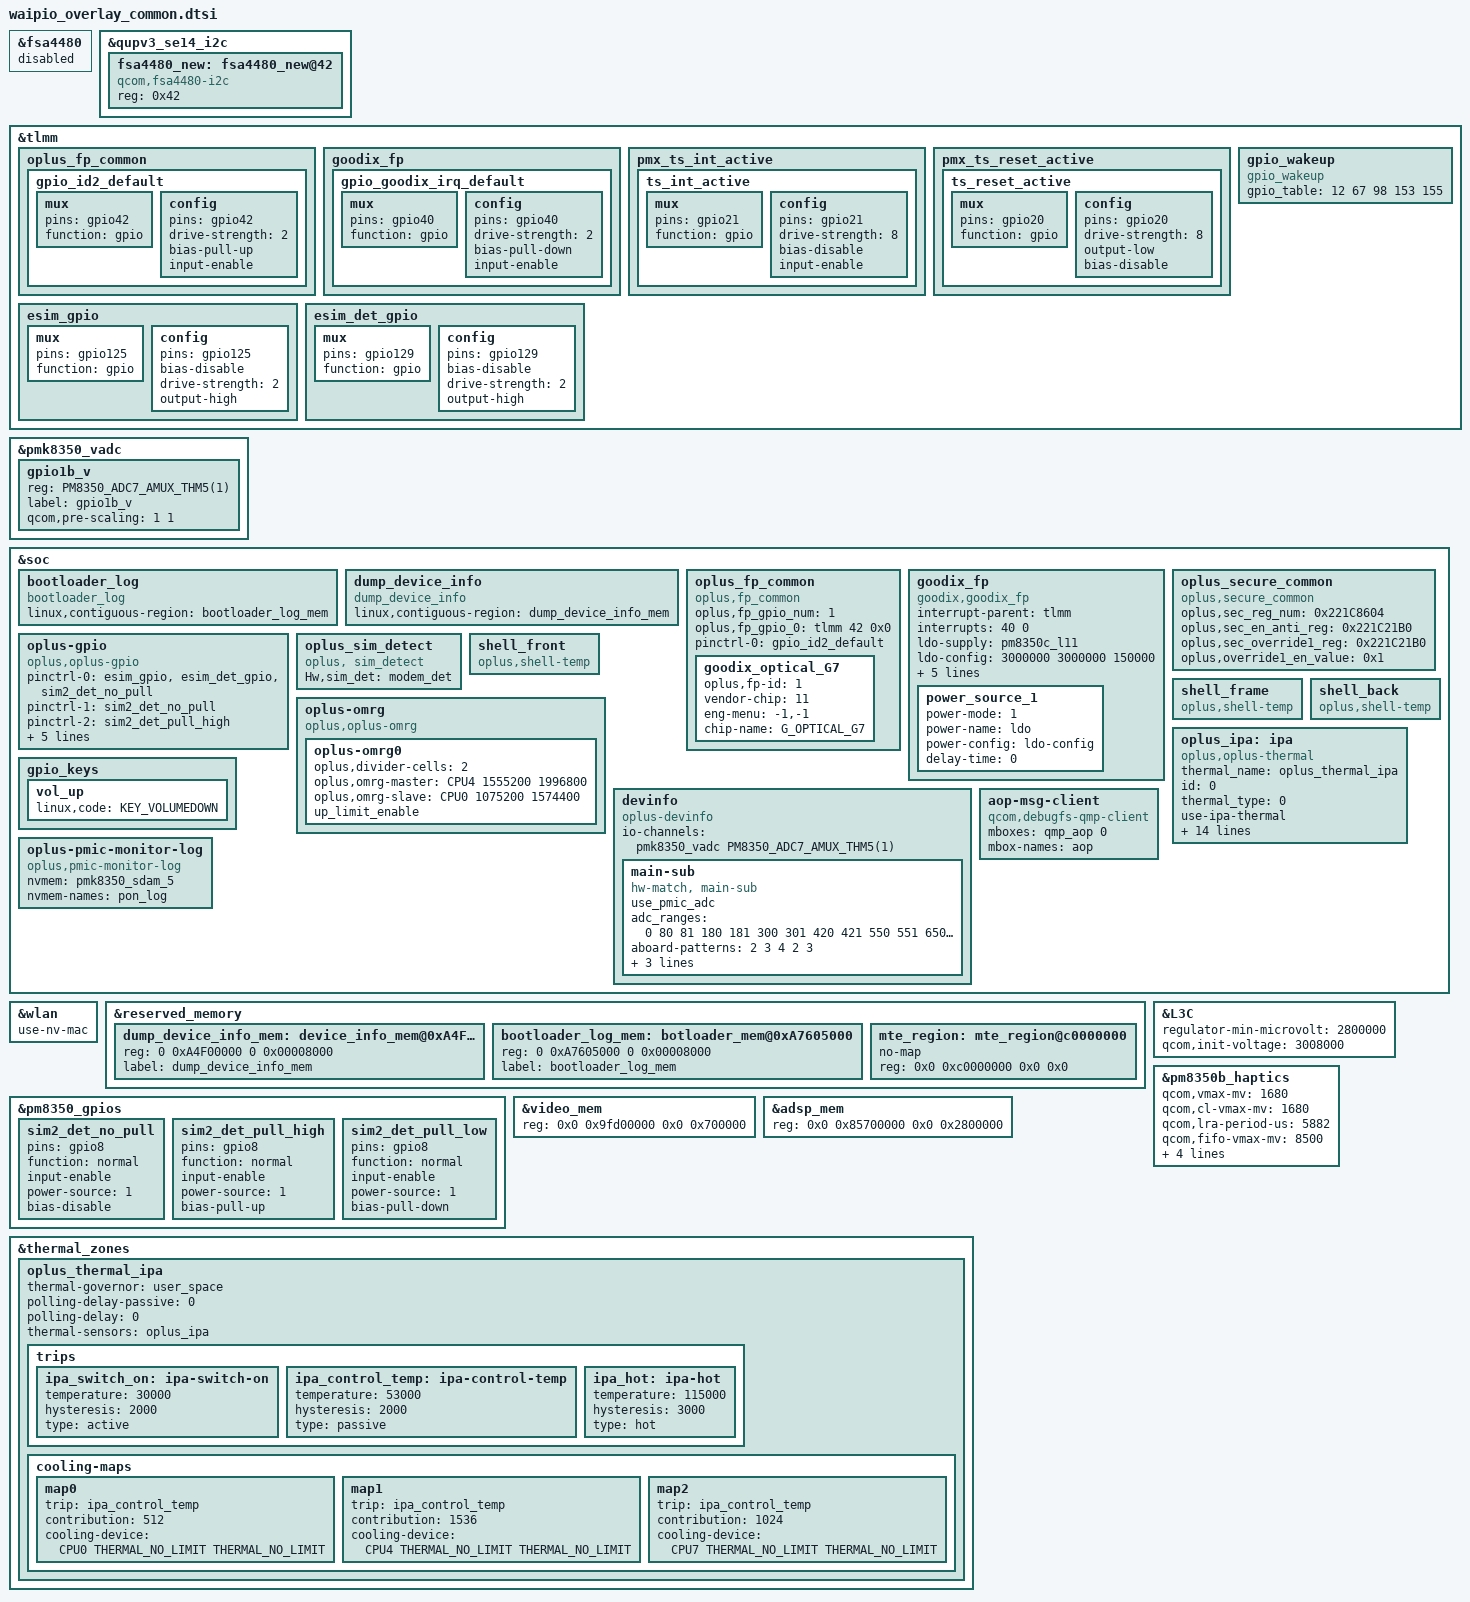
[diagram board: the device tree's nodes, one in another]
/* #ifdef OPLUS_ARCH_EXTENDS */
&fsa4480 {
	status = "disabled";
};

&qupv3_se14_i2c {
	status = "ok";
	fsa4480_new: fsa4480_new@42 {
		status = "ok";
		compatible = "qcom,fsa4480-i2c";
		reg = <0x42>;
	};
};
/* OPLUS_ARCH_EXTENDS */

//waipio-pinctrl.dtsi
&tlmm {
    //#ifdef OPLUS_FEATURE_FINGERPRINT
	oplus_fp_common{
		gpio_id2_default: gpio_id2_default {
			mux {
				pins = "gpio42";
				function = "gpio";
			};
			config {
				pins = "gpio42";
				drive-strength = <2>;
				bias-pull-up;
				input-enable;
			};
		};
	};
	goodix_fp{
		gpio_goodix_irq_default: gpio_goodix_irq_default {
			mux {
				pins = "gpio40";
				function = "gpio";
			};
			config {
				pins = "gpio40";
				drive-strength = <2>;
				bias-pull-down;
				input-enable;
			};
		};
	};
	//#endif /*OPLUS_FEATURE_FINGERPRINT*/

	pmx_ts_int_active {
		ts_int_active: ts_int_active {
			mux {
				pins = "gpio21";
				function = "gpio";
			};

			config {
				pins = "gpio21";
				drive-strength = <8>;
				bias-disable;
				input-enable;
			};
		};
	};

	pmx_ts_reset_active {
		ts_reset_active: ts_reset_active {
			mux {
				pins = "gpio20";
				function = "gpio";
			};

			config {
				pins = "gpio20";
				drive-strength = <8>;
				output-low;
				bias-disable;
			};
		};
	};

	gpio_wakeup: gpio_wakeup {
		compatible = "gpio_wakeup";
		gpio_table = <12 67 98 153 155>;
	};
//#endif /*OPLUS_FEATURE_TP_BASIC*/
};

&pmk8350_vadc {
	gpio1b_v {
		reg = <PM8350_ADC7_AMUX_THM5(1)>;
		label = "gpio1b_v";
		qcom,pre-scaling = <1 1>;
	};
};

//waipio.dtsi


&soc {
	bootloader_log {
		compatible = "bootloader_log";
		linux,contiguous-region = <&bootloader_log_mem>;
	};
/* #ifdef OPLUS_FEATURE_DUMP_DEVICE_INFO */
	dump_device_info {
		compatible = "dump_device_info";
		linux,contiguous-region = <&dump_device_info_mem>;
	};
/* #endif OPLUS_FEATURE_DUMP_DEVICE_INFO */
	//#ifdef OPLUS_FEATURE_FINGERPRINT
	oplus_fp_common {
		compatible = "oplus,fp_common";
		oplus,fp_gpio_num = <1>;
		oplus,fp_gpio_0 = <&tlmm 42 0x0>;
		pinctrl-names = "default";
		pinctrl-0 = <&gpio_id2_default>;
		goodix_optical_G7 {
			oplus,fp-id = <1>; /* fp id mapping table */
			vendor-chip = <11>; /* please refer to the struct fp_vendor_t in oplus_fp_commmon.n */
			eng-menu = "-1,-1"; /* represents SNR, inclination test item in engineer menu, and 0/1 means off/on */
			chip-name = "G_OPTICAL_G7";  /* /proc/fp_id, will be displayed in engineer menu  */
		};
	};
	goodix_fp {
		status = "ok";
		compatible = "goodix,goodix_fp";
		interrupt-parent = <&tlmm>;
		interrupts = <40 0>;
		ldo-supply = <&pm8350c_l11>;
		ldo-config = <3000000 3000000 150000>;
		goodix,gpio_irq = <&tlmm 40 0x1>;
		goodix,gpio_reset = <&tlmm 41 0x0>;
		pinctrl-names = "default";
		pinctrl-0 = <&gpio_goodix_irq_default>;
		notify_tpinfo_flag = <1>;
		power-num = <1>;
		power_source_1 {
			power-mode = <1>;
			power-name = "ldo";
			power-config = "ldo-config";
			delay-time = <0>;
		};
	};
	//#endif /*OPLUS_FEATURE_FINGERPRINT*/
	//#ifdef OPLUS_FEATURE_SECURITY_COMMON
	/* 2021/09/04 add for oplus secure */
	oplus_secure_common {
		compatible = "oplus,secure_common";
		oplus,sec_reg_num = <0x221C8604>;
		oplus,sec_en_anti_reg = <0x221C21B0>;
		oplus,sec_override1_reg = <0x221C21B0>;
		oplus,override1_en_value = <0x1>;
	};
	//#endif /*OPLUS_FEATURE_SECURITY_COMMON*/

	//#ifdef OPLUS_FEATRUE_ESIM
	oplus-gpio {
		compatible = "oplus,oplus-gpio";
		pinctrl-names = "default", "sim2_det_no_pull", "sim2_det_pull_high", "sim2_det_pull_low";
		pinctrl-0 = <&esim_gpio &esim_det_gpio &sim2_det_no_pull>;
		pinctrl-1 = <&sim2_det_no_pull>;
		pinctrl-2 = <&sim2_det_pull_high>;
		pinctrl-3 = <&sim2_det_pull_low>;
		oplus,oplus-gpio-esim = <&tlmm 125 0>;
		oplus,oplus-esim-det = <&tlmm 129 0>;
		oplus,oplus-sim2-det = <&pm8350_gpios 8 0>;
		oplus,uim-reset-pin = "modem_solution";
	};
	//#endif /* OPLUS_FEATRUE_ESIM */

	//#ifdef OPLUS_FEATRUE_SIM_HOLDER_DETECT
	oplus_sim_detect {
		compatible = "oplus, sim_detect";
		Hw,sim_det = "modem_det";
	};
	//#endif /* OPLUS_FEATRUE_SIM_HOLDER_DETECT */

	//#ifdef OPLUS_FEATURE_THERMAL_HORAE
	shell_front {
		compatible = "oplus,shell-temp";
	};

	shell_frame {
		compatible = "oplus,shell-temp";
	};

	shell_back {
		compatible = "oplus,shell-temp";
	};
	//#endif

	//#ifdef CONFIG_OPLUS_OMRG
	oplus-omrg {
		compatible = "oplus,oplus-omrg";
		oplus-omrg0 {
			oplus,divider-cells = <2>;
			oplus,omrg-master = <&CPU4 1555200 1996800>;
			oplus,omrg-slave = <&CPU0 1075200 1574400>;
			up_limit_enable;
			/* down_limit_enable; */
			/* thermal_enable; */
		};
	};
	//#endif

	//#ifdef CONFIG_OPLUS_IPA_THERMAL
	oplus_ipa: ipa {
		compatible = "oplus,oplus-thermal";
		thermal_name = "oplus_thermal_ipa";
		id = <0>;
		thermal_type = <0>;
		#thermal-sensor-cells = <0>;
		use-ipa-thermal;
		use-power-budget = <1>;
		polling_delay_on = <100>;
		polling_delay_off = <3000>;
		k_po = <1>;
		k_pu = <1>;
		k_i = <1>;
		k_d = <0>;
		i_max = <2>;
		integral_cutoff = <10>;
		sustainable_power = <9999>;
		thermal_work_affinity = "0-7";
		cdev_min_power = <200 410 210 0 0 0>;
		use-thermalcontrol-limit = <1>;
		clt_state_limit = <0 0 0 0 0 0>;
	};
	//#endif

	gpio_keys {
		vol_up {
			linux,code = <KEY_VOLUMEDOWN>;
//#endif /*OPLUS_FEATURE_TP_BASIC*/
		};
	};

	devinfo {
		compatible = "oplus-devinfo";

		//pinctrl-names = "active", "sleep";
		//pinctrl-0 = <&hw_id_active>;
		//pinctrl-1 = <&hw_id_sleep>;

		io-channels= <&pmk8350_vadc PM8350_ADC7_AMUX_THM5(1)>;
		io-channel-names= "vph_pwr_voltage_sub";

		main-sub {
			compatible = "hw-match, main-sub";
			use_pmic_adc;
			adc_ranges = <0 80
					81 180
					181 300
					301 420
					421 550
					551 650
					651 760
					761 850
					851 950
					951 1050
					1051 1150
					1151 1300>;
			aboard-patterns = <2 3 4 2 3>;

			/*main board*/
			match-projects = <21001 21001 21201 21001 21001>;

			/*rf type*/
			rf_match_support;
			rf-patterns = <1 2 3 4 5>;
		};
	};

	aop-msg-client {
		compatible = "qcom,debugfs-qmp-client";
		mboxes = <&qmp_aop 0>;
		mbox-names = "aop";
	};

	//#ifdef CONFIG_OPLUS_FEATURE_PMIC_MONITOR, read pmic info from nvmem(only for xblloader close)
		oplus-pmic-monitor-log {
			compatible = "oplus,pmic-monitor-log";
			nvmem = <&pmk8350_sdam_5>;
			nvmem-names = "pon_log";
		};
	//#endif
};

//#ifdef OPLUS_FEATURE_WIFI_MAC
&wlan {
	use-nv-mac;
};
//#endif /* OPLUS_FEATURE_WIFI_MAC */

//#ifdef OPLUS_BUG_STABILITY
&reserved_memory {
/*
	ramoops: ramoops@0xa1f00000 {
		compatible = "ramoops";
		reg = <0 0xa1f00000 0 0x00100000>;  //1M
		console-size = <0x40000>; //256k
	};
*/
/* #ifdef OPLUS_FEATURE_DUMP_DEVICE_INFO */
	dump_device_info_mem: device_info_mem@0xA4F00000 {
		reg = <0 0xA4F00000 0 0x00008000>;
		label = "dump_device_info_mem";
	};
/* #endif OPLUS_FEATURE_DUMP_DEVICE_INFO */
	/*
	This size is from
	boot_images/boot/QcomPkg/SocPkg/Waipio/Common/uefiplat.cfg
	0xA7605000, 0x00008000, "Log Buffer",        AddMem, SYS_MEM, SYS_MEM_CAP, RtData, WRITE_BACK_XN
	so we reserve this for bootloader log
	*/
	bootloader_log_mem: botloader_mem@0xA7605000 {
		reg = <0 0xA7605000 0 0x00008000>;
		label = "bootloader_log_mem";
	};

	mte_region: mte_region@c0000000 {
		no-map;
		reg = <0x0 0xc0000000 0x0 0x0>;
	};
};

&tlmm {
	//#ifdef OPLUS_FEATRUE_ESIM
	esim_gpio: esim_gpio {
		mux {
			pins = "gpio125";
			function = "gpio";
		};
		config {
			pins = "gpio125";
			bias-disable; /* NO pull */
			drive-strength = <2>; /* 2 MA */
			output-high;
		};
	};

	esim_det_gpio: esim_det_gpio {
		mux {
			pins = "gpio129";
			function = "gpio";
		};
		config {
			pins = "gpio129";
			bias-disable; /* NO pull */
			drive-strength = <2>; /* 2 MA */
			output-high;
		};
	};
	//#endif /* OPLUS_FEATRUE_ESIM */
};

&L3C {
	regulator-min-microvolt = <2800000>;
	qcom,init-voltage = <3008000>;
};

&pm8350_gpios {
	//#ifdef OPLUS_FEATRUE_DUAL_SIM_DETECT
	sim2_det_no_pull: sim2_det_no_pull {
			pins = "gpio8";
			function = "normal";
			input-enable;
			power-source = <1>;
			bias-disable;
	};

	sim2_det_pull_high: sim2_det_pull_high {
			pins = "gpio8";
			function = "normal";
			input-enable;
			power-source = <1>;
			bias-pull-up;
	};

	sim2_det_pull_low: sim2_det_pull_low {
			pins = "gpio8";
			function = "normal";
			input-enable;
			power-source = <1>;
			bias-pull-down;
	};
	//#endif OPLUS_FEATRUE_DUAL_SIM_DETECT
};

&pm8350b_haptics {
//#ifdef OPLUS_FEATURE_CHG_BASIC
	qcom,vmax-mv = <1680>;
	qcom,cl-vmax-mv = <1680>;
	qcom,lra-period-us = <5882>;
	qcom,fifo-vmax-mv = <8500>;
	qcom,old-steady-vmax-mv = <8500>;
	qcom,cal-data-restore;
	qcom,fifo-empty-threshold = <480>;
//#endif
	qcom,vibrator-type = <8151>;//sla0815
};

//waipio.dtsi
/* #ifdef OPLUS_ARCH_EXTENDS */
&video_mem {
	reg = <0x0 0x9fd00000 0x0 0x700000>;
};

&adsp_mem {
	reg = <0x0 0x85700000 0x0 0x2800000>;
};
/* OPLUS_ARCH_EXTENDS */

//#ifdef CONFIG_OPLUS_IPA_THERMAL
&thermal_zones {
	oplus_thermal_ipa {
		thermal-governor = "user_space";
		polling-delay-passive = <0>;
		polling-delay = <0>;
		thermal-sensors = <&oplus_ipa>;
		trips {
			ipa_switch_on: ipa-switch-on {
				temperature = <30000>;
				hysteresis = <2000>;
				type = "active";
			};
			ipa_control_temp: ipa-control-temp {
				temperature = <53000>;
				hysteresis = <2000>;
				type = "passive";
			};
			ipa_hot: ipa-hot {
				temperature = <115000>;
				hysteresis = <3000>;
				type = "hot";
			};
		};
		cooling-maps {
			map0 {
				trip = <&ipa_control_temp>;
				contribution = <512>;
				cooling-device = <&CPU0 THERMAL_NO_LIMIT THERMAL_NO_LIMIT>;
			};
			map1 {
				trip = <&ipa_control_temp>;
				contribution = <1536>;
				cooling-device = <&CPU4 THERMAL_NO_LIMIT THERMAL_NO_LIMIT>;
			};
			map2 {
				trip = <&ipa_control_temp>;
				contribution = <1024>;
				cooling-device = <&CPU7 THERMAL_NO_LIMIT THERMAL_NO_LIMIT>;
			};
		};
	};
};
//#endif
